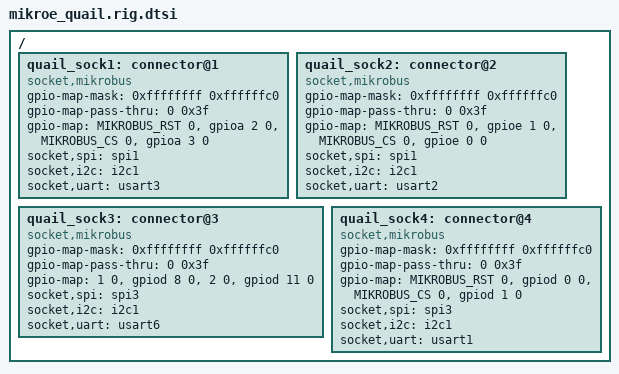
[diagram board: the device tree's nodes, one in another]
/* Board-DT fragment: MikroE Quail — four typed mikroBUS sockets.
 * Part of the BOARD tree: real phandles, upstreamable as plain DT.
 * Replaces the 16-label matrix (mikroe_quail.dts:335-365); the per-socket
 * nexus nodes Quail already has upstream become these socket nodes.
 * gpio-map truncated to CS/RST for the trial.
 */

#include <dt-bindings/connector/mikrobus.h>

/ {
	quail_sock1: connector@1 {
		compatible = "socket,mikrobus";
		#gpio-cells = <2>;
		gpio-map-mask = <0xffffffff 0xffffffc0>;
		gpio-map-pass-thru = <0 0x3f>;
		gpio-map = <MIKROBUS_RST 0 &gpioa 2 0>,
			   <MIKROBUS_CS  0 &gpioa 3 0>;
		socket,spi = <&spi1>;
		socket,i2c = <&i2c1>;
		socket,uart = <&usart3>;
	};
	quail_sock2: connector@2 {
		compatible = "socket,mikrobus";
		#gpio-cells = <2>;
		gpio-map-mask = <0xffffffff 0xffffffc0>;
		gpio-map-pass-thru = <0 0x3f>;
		gpio-map = <MIKROBUS_RST 0 &gpioe 1 0>,
			   <MIKROBUS_CS  0 &gpioe 0 0>;
		socket,spi = <&spi1>;
		socket,i2c = <&i2c1>;
		socket,uart = <&usart2>;
	};
	quail_sock3: connector@3 {
		compatible = "socket,mikrobus";
		#gpio-cells = <2>;
		gpio-map-mask = <0xffffffff 0xffffffc0>;
		gpio-map-pass-thru = <0 0x3f>;
		gpio-map = <1 0 &gpiod 8  0>,
			   <2 0 &gpiod 11 0>;
		socket,spi = <&spi3>;
		socket,i2c = <&i2c1>;
		socket,uart = <&usart6>;
	};
	quail_sock4: connector@4 {
		compatible = "socket,mikrobus";
		#gpio-cells = <2>;
		gpio-map-mask = <0xffffffff 0xffffffc0>;
		gpio-map-pass-thru = <0 0x3f>;
		gpio-map = <MIKROBUS_RST 0 &gpiod 0 0>,
			   <MIKROBUS_CS  0 &gpiod 1 0>;
		socket,spi = <&spi3>;
		socket,i2c = <&i2c1>;
		socket,uart = <&usart1>;
	};
};
